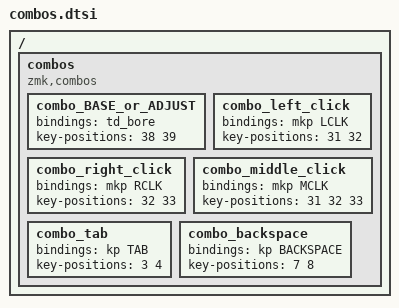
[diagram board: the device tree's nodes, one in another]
/ {
    combos {
        compatible = "zmk,combos";

        combo_BASE_or_ADJUST {
            bindings = <&td_bore>;
            key-positions = <38 39>;
        };

        combo_left_click {
            bindings = <&mkp LCLK>;
            key-positions = <31 32>;
        };

        combo_right_click {
            bindings = <&mkp RCLK>;
            key-positions = <32 33>;
        };

        combo_middle_click {
            bindings = <&mkp MCLK>;
            key-positions = <31 32 33>;
        };

        combo_tab {
            bindings = <&kp TAB>;
            key-positions = <3 4>;
        };

        combo_backspace {
            bindings = <&kp BACKSPACE>;
            key-positions = <7 8>;
        };
    };
};
